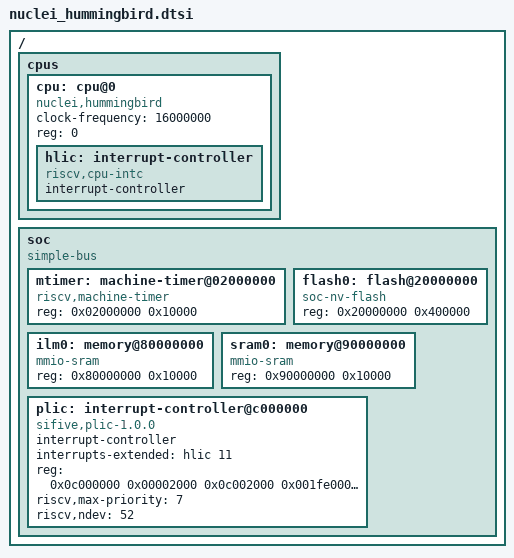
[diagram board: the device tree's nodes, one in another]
/*
 * Copyright (c) 2021 TOKITA Hiroshi
 *
 * SPDX-License-Identifier: Apache-2.0
 */

/ {
	#address-cells = <1>;
	#size-cells = <1>;

	cpus {
		#address-cells = <1>;
		#size-cells = <0>;

		cpu: cpu@0 {
			clock-frequency = <16000000>;
			compatible = "nuclei,hummingbird", "riscv";
			device_type = "cpu";
			reg = <0>;
			hlic: interrupt-controller {
				#interrupt-cells = <1>;
				compatible = "riscv,cpu-intc";
				interrupt-controller;
			};
		};
	};

	soc {
		#address-cells = <1>;
		#size-cells = <1>;
		compatible = "simple-bus";
		ranges;

		mtimer: machine-timer@02000000 {
			compatible = "riscv,machine-timer";
			reg = <0x02000000 0x10000>;
		};

		flash0: flash@20000000 {
			compatible = "soc-nv-flash";
			reg = <0x20000000 0x400000>;
		};

		ilm0: memory@80000000 {
			compatible = "mmio-sram";
			reg = <0x80000000 0x10000>;
		};

		sram0: memory@90000000 {
			compatible = "mmio-sram";
			reg = <0x90000000 0x10000>;
		};

		plic: interrupt-controller@c000000 {
			#interrupt-cells = <2>;
			compatible = "sifive,plic-1.0.0";
			interrupt-controller;
			interrupts-extended = <&hlic 11>;
			reg = <0x0c000000 0x00002000
			       0x0c002000 0x001fe000
			       0x0c200000 0x03e00000>;
			reg-names = "prio", "irq_en", "reg";
			riscv,max-priority = <7>;
			riscv,ndev = <52>;
		};
	};
};
